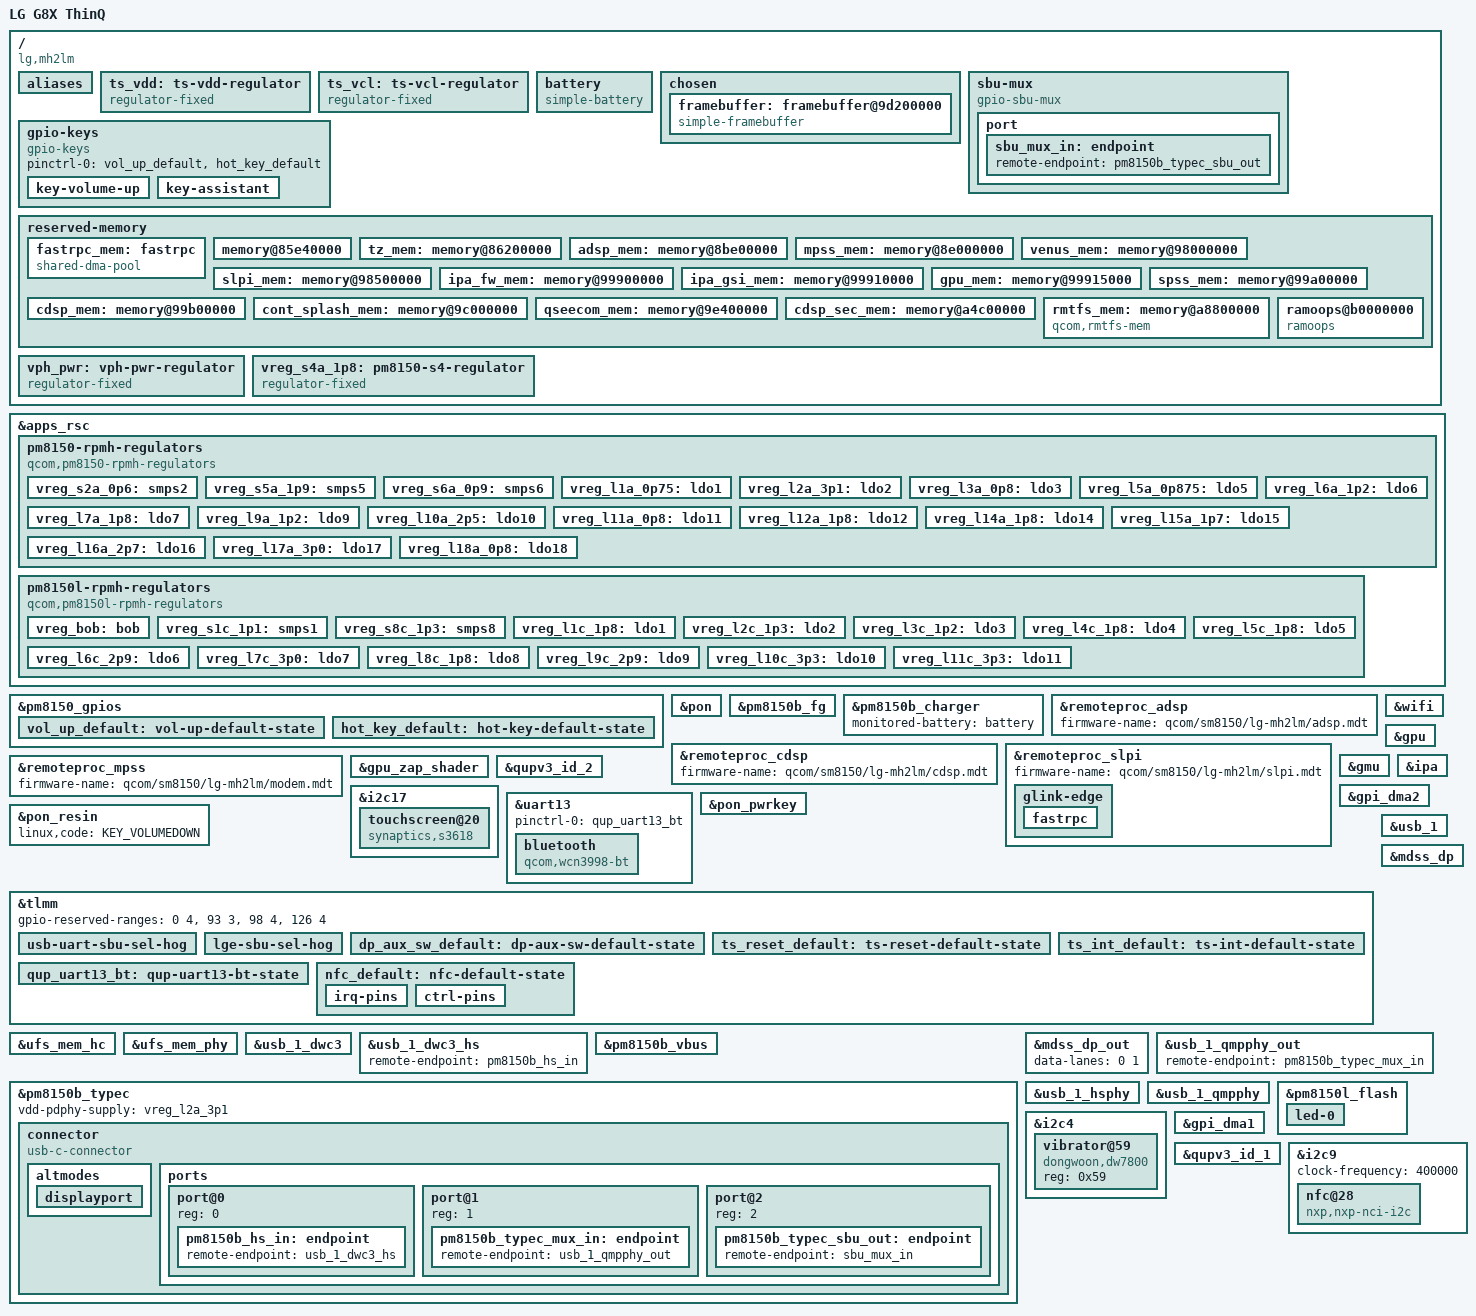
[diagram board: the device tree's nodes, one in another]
// SPDX-License-Identifier: BSD-3-Clause
/*
 * LG G8X ThinQ (mh2lm), first-boot device tree.
 *
 * Reserved memory and regulator limits come from LG's downstream kernel
 * (LineageOS android_kernel_lge_sm8150, lineage-22.2). Regulator structure is
 * based on sm8150-xiaomi-cepheus.dts by Alexey Minnekhanov.
 * Scope: simple framebuffer, buttons, USB gadget, UFS, pstore.
 */

/dts-v1/;

#include <dt-bindings/arm/qcom,ids.h>
#include <dt-bindings/firmware/qcom,scm.h>
#include <dt-bindings/gpio/gpio.h>
#include <dt-bindings/input/input.h>
#include <dt-bindings/input/gpio-keys.h>
#include <dt-bindings/leds/common.h>
#include <dt-bindings/pinctrl/qcom,pmic-gpio.h>
#include <dt-bindings/regulator/qcom,rpmh-regulator.h>
#include <dt-bindings/usb/pd.h>
#include "sm8150.dtsi"
#include "pm8150.dtsi"
#include "pm8150b.dtsi"
#include "pm8150l.dtsi"

/delete-node/ &tz_mem;      /* LG reserves more; the upstream size leaves secure memory mapped */
/delete-node/ &rmtfs_mem;   /* falls inside LG tz_mem; revisit for modem */
/delete-node/ &adsp_mem;
/delete-node/ &mpss_mem;
/delete-node/ &venus_mem;
/delete-node/ &slpi_mem;
/delete-node/ &ipa_fw_mem;
/delete-node/ &ipa_gsi_mem;
/delete-node/ &gpu_mem;
/delete-node/ &spss_mem;
/delete-node/ &cdsp_mem;
/delete-node/ &qseecom_mem;

/ {
	model = "LG G8X ThinQ";
	compatible = "lg,mh2lm", "qcom,sm8150";
	chassis-type = "handset";

	/* Generic board-id, as in the Renegade image LG ABL accepts */
	qcom,msm-id = <QCOM_ID_SM8150 0x20000>;
	qcom,board-id = <0 0>;

	aliases {
		hsuart0 = &uart13;
		display0 = &framebuffer;
	};

	ts_vdd: ts-vdd-regulator {
		compatible = "regulator-fixed";
		regulator-name = "ts_vdd";
		gpio = <&tlmm 152 GPIO_ACTIVE_HIGH>;
		enable-active-high;
		regulator-boot-on;
		regulator-always-on;
	};

	ts_vcl: ts-vcl-regulator {
		compatible = "regulator-fixed";
		regulator-name = "ts_vcl";
		gpio = <&tlmm 59 GPIO_ACTIVE_HIGH>;
		enable-active-high;
		regulator-boot-on;
		regulator-always-on;
	};

	battery: battery {
		compatible = "simple-battery";
		charge-full-design-microamp-hours = <4000000>;
		voltage-min-design-microvolt = <3400000>;
		voltage-max-design-microvolt = <4400000>;
	};

	chosen {
		#address-cells = <2>;
		#size-cells = <2>;
		ranges;

		framebuffer: framebuffer@9d200000 {
			compatible = "simple-framebuffer";
			reg = <0 0x9d200000 0 0x1200000>;
			width = <1080>;
			height = <2340>;
			stride = <(1080 * 4)>;
			format = "a8r8g8b8";
			clocks = <&gcc GCC_DISP_HF_AXI_CLK>,
				 <&gcc GCC_DISP_SF_AXI_CLK>;
		};
	};

	/*
	 * USB-C SBU <-> DP AUX switch. LG drives it with two GPIOs (stock DT
	 * sde_dp qcom,aux-en-gpio 42, enable when low; qcom,aux-sel-gpio 148,
	 * set for the flipped orientation), which is what gpio-sbu-mux does.
	 */
	sbu-mux {
		compatible = "gpio-sbu-mux";
		enable-gpios = <&tlmm 42 GPIO_ACTIVE_LOW>;
		select-gpios = <&tlmm 148 GPIO_ACTIVE_HIGH>;
		pinctrl-0 = <&dp_aux_sw_default>;
		pinctrl-names = "default";
		mode-switch;
		orientation-switch;

		port {
			sbu_mux_in: endpoint {
				remote-endpoint = <&pm8150b_typec_sbu_out>;
			};
		};
	};

	gpio-keys {
		compatible = "gpio-keys";
		pinctrl-names = "default";
		pinctrl-0 = <&vol_up_default &hot_key_default>;

		key-volume-up {
			label = "Volume Up";
			gpios = <&pm8150_gpios 6 GPIO_ACTIVE_LOW>;
			linux,code = <KEY_VOLUMEUP>;
			debounce-interval = <15>;
			wakeup-source;
		};

		key-assistant {
			label = "Google Assistant";
			gpios = <&pm8150_gpios 1 GPIO_ACTIVE_LOW>;
			linux,code = <KEY_ASSISTANT>;
			debounce-interval = <15>;
		};
	};

	reserved-memory {
		fastrpc_mem: fastrpc {
			compatible = "shared-dma-pool";
			alloc-ranges = <0x0 0x00000000 0x0 0xffffffff>;
			alignment = <0x0 0x400000>;
			size = <0x0 0x1000000>;
			reusable;
		};

		/* Tail of LG xbl_aop_mem not covered by the upstream xbl/aop regions */
		memory@85e40000 {
			reg = <0x0 0x85e40000 0x0 0xc0000>;
			no-map;
		};

		tz_mem: memory@86200000 {
			reg = <0x0 0x86200000 0x0 0x5500000>;
			no-map;
		};

		adsp_mem: memory@8be00000 {
			reg = <0x0 0x8be00000 0x0 0x2200000>;
			no-map;
		};

		mpss_mem: memory@8e000000 {
			reg = <0x0 0x8e000000 0x0 0xa000000>;
			no-map;
		};

		venus_mem: memory@98000000 {
			reg = <0x0 0x98000000 0x0 0x500000>;
			no-map;
		};

		slpi_mem: memory@98500000 {
			reg = <0x0 0x98500000 0x0 0x1400000>;
			no-map;
		};

		ipa_fw_mem: memory@99900000 {
			reg = <0x0 0x99900000 0x0 0x10000>;
			no-map;
		};

		ipa_gsi_mem: memory@99910000 {
			reg = <0x0 0x99910000 0x0 0x5000>;
			no-map;
		};

		gpu_mem: memory@99915000 {
			reg = <0x0 0x99915000 0x0 0x2000>;
			no-map;
		};

		spss_mem: memory@99a00000 {
			reg = <0x0 0x99a00000 0x0 0x100000>;
			no-map;
		};

		cdsp_mem: memory@99b00000 {
			reg = <0x0 0x99b00000 0x0 0x1400000>;
			no-map;
		};

		cont_splash_mem: memory@9c000000 {
			reg = <0x0 0x9c000000 0x0 0x2400000>;
			no-map;
		};

		qseecom_mem: memory@9e400000 {
			reg = <0x0 0x9e400000 0x0 0x1c00000>;
			no-map;
		};

		cdsp_sec_mem: memory@a4c00000 {
			reg = <0x0 0xa4c00000 0x0 0x3c00000>;
			no-map;
		};

		rmtfs_mem: memory@a8800000 {
			compatible = "qcom,rmtfs-mem";
			reg = <0x0 0xa8800000 0x0 0x200000>;
			no-map;

			qcom,client-id = <1>;
			qcom,vmid = <15>;
		};

		ramoops@b0000000 {
			compatible = "ramoops";
			reg = <0x0 0xb0000000 0x0 0x300000>;
			record-size = <0x1000>;
			console-size = <0x40000>;
			ftrace-size = <0x40000>;
			pmsg-size = <0x200000>;
			ecc-size = <0>;
		};
	};

	vph_pwr: vph-pwr-regulator {
		compatible = "regulator-fixed";
		regulator-name = "vph_pwr";
		regulator-min-microvolt = <3700000>;
		regulator-max-microvolt = <3700000>;
	};

	/* S4 is modeled as a fixed regulator in vendor sources */
	vreg_s4a_1p8: pm8150-s4-regulator {
		compatible = "regulator-fixed";
		regulator-name = "vreg_s4a_1p8";
		regulator-min-microvolt = <1800000>;
		regulator-max-microvolt = <1800000>;
		regulator-always-on;
		regulator-boot-on;
		vin-supply = <&vph_pwr>;
	};
};

&apps_rsc {
	pm8150-rpmh-regulators {
		compatible = "qcom,pm8150-rpmh-regulators";
		qcom,pmic-id = "a";

		vdd-s1-supply = <&vph_pwr>;
		vdd-s2-supply = <&vph_pwr>;
		vdd-s3-supply = <&vph_pwr>;
		vdd-s4-supply = <&vph_pwr>;
		vdd-s5-supply = <&vph_pwr>;
		vdd-s6-supply = <&vph_pwr>;
		vdd-s7-supply = <&vph_pwr>;
		vdd-s8-supply = <&vph_pwr>;
		vdd-s9-supply = <&vph_pwr>;
		vdd-s10-supply = <&vph_pwr>;

		vdd-l1-l8-l11-supply = <&vreg_s6a_0p9>;
		vdd-l2-l10-supply = <&vreg_bob>;
		vdd-l3-l4-l5-l18-supply = <&vreg_s6a_0p9>;
		vdd-l6-l9-supply = <&vreg_s8c_1p3>;
		vdd-l7-l12-l14-l15-supply = <&vreg_s5a_1p9>;
		vdd-l13-l16-l17-supply = <&vreg_bob>;

		vreg_s2a_0p6: smps2 {
			regulator-min-microvolt = <600000>;
			regulator-max-microvolt = <600000>;
			regulator-initial-mode = <RPMH_REGULATOR_MODE_HPM>;
			regulator-name = "pm8150_s2a_0p6";
		};

		vreg_s5a_1p9: smps5 {
			regulator-min-microvolt = <1904000>;
			regulator-max-microvolt = <2040000>;
			regulator-initial-mode = <RPMH_REGULATOR_MODE_HPM>;
			regulator-name = "pm8150_s5a_0p6";
		};

		vreg_s6a_0p9: smps6 {
			regulator-min-microvolt = <920000>;
			regulator-max-microvolt = <1128000>;
			regulator-initial-mode = <RPMH_REGULATOR_MODE_HPM>;
			regulator-name = "pm8150_s6a_0p9";
		};

		vreg_l1a_0p75: ldo1 {
			regulator-min-microvolt = <752000>;
			regulator-max-microvolt = <752000>;
			regulator-initial-mode = <RPMH_REGULATOR_MODE_HPM>;
			regulator-name = "pm8150_l1a_0p75";
		};

		vreg_l2a_3p1: ldo2 {
			regulator-min-microvolt = <3072000>;
			regulator-max-microvolt = <3072000>;
			regulator-initial-mode = <RPMH_REGULATOR_MODE_HPM>;
			regulator-name = "pm8150_l2a_3p1";
		};

		vreg_l3a_0p8: ldo3 {
			regulator-min-microvolt = <480000>;
			regulator-max-microvolt = <932000>;
			regulator-initial-mode = <RPMH_REGULATOR_MODE_HPM>;
			regulator-name = "pm8150_l3a_0p8";
		};

		vreg_l5a_0p875: ldo5 {
			regulator-min-microvolt = <880000>;
			regulator-max-microvolt = <880000>;
			regulator-initial-mode = <RPMH_REGULATOR_MODE_HPM>;
			regulator-name = "pm8150_l5a_0p875";
		};

		vreg_l6a_1p2: ldo6 {
			regulator-min-microvolt = <1200000>;
			regulator-max-microvolt = <1200000>;
			regulator-initial-mode = <RPMH_REGULATOR_MODE_HPM>;
			regulator-name = "pm8150_l6a_1p2";
		};

		vreg_l7a_1p8: ldo7 {
			regulator-min-microvolt = <1800000>;
			regulator-max-microvolt = <1800000>;
			regulator-initial-mode = <RPMH_REGULATOR_MODE_HPM>;
			regulator-name = "pm8150_l7a_1p8";
		};

		vreg_l9a_1p2: ldo9 {
			regulator-min-microvolt = <1200000>;
			regulator-max-microvolt = <1200000>;
			regulator-initial-mode = <RPMH_REGULATOR_MODE_HPM>;
			regulator-name = "pm8150_l9a_1p2";
		};

		vreg_l10a_2p5: ldo10 {
			regulator-min-microvolt = <2950000>;
			regulator-max-microvolt = <2960000>;
			regulator-initial-mode = <RPMH_REGULATOR_MODE_HPM>;
			regulator-name = "pm8150_l10a_2p5";
		};

		vreg_l11a_0p8: ldo11 {
			regulator-min-microvolt = <800000>;
			regulator-max-microvolt = <800000>;
			regulator-initial-mode = <RPMH_REGULATOR_MODE_HPM>;
			regulator-name = "pm8150_l11a_0p8";
		};

		vreg_l12a_1p8: ldo12 {
			regulator-min-microvolt = <1800000>;
			regulator-max-microvolt = <1800000>;
			regulator-initial-mode = <RPMH_REGULATOR_MODE_HPM>;
			regulator-name = "pm8150_l12a_1p8";
		};

		/* L13 is unused, but min/max are 3000000 for it. */

		vreg_l14a_1p8: ldo14 {
			regulator-min-microvolt = <1800000>;
			regulator-max-microvolt = <1880000>;
			regulator-initial-mode = <RPMH_REGULATOR_MODE_HPM>;
			regulator-name = "pm8150_l14a_1p8";
			regulator-always-on;
		};

		vreg_l15a_1p7: ldo15 {
			regulator-min-microvolt = <1704000>;
			regulator-max-microvolt = <1704000>;
			regulator-initial-mode = <RPMH_REGULATOR_MODE_HPM>;
			regulator-name = "pm8150_l15a_1p7";
		};

		vreg_l16a_2p7: ldo16 {
			regulator-min-microvolt = <2704000>;
			regulator-max-microvolt = <2960000>;
			regulator-initial-mode = <RPMH_REGULATOR_MODE_HPM>;
			regulator-name = "pm8150_l16a_2p7";
		};

		vreg_l17a_3p0: ldo17 {
			regulator-min-microvolt = <2856000>;
			regulator-max-microvolt = <3008000>;
			regulator-initial-mode = <RPMH_REGULATOR_MODE_HPM>;
			regulator-name = "pm8150_l17a_3p0";
			regulator-always-on;
		};

		vreg_l18a_0p8: ldo18 {
			regulator-min-microvolt = <880000>;
			regulator-max-microvolt = <912000>;
			regulator-initial-mode = <RPMH_REGULATOR_MODE_HPM>;
			regulator-name = "pm8150_l18a_0p8";
		};
	};

	pm8150l-rpmh-regulators {
		compatible = "qcom,pm8150l-rpmh-regulators";
		qcom,pmic-id = "c";

		vdd-s1-supply = <&vph_pwr>;
		vdd-s2-supply = <&vph_pwr>;
		vdd-s3-supply = <&vph_pwr>;
		vdd-s4-supply = <&vph_pwr>;
		vdd-s5-supply = <&vph_pwr>;
		vdd-s6-supply = <&vph_pwr>;
		vdd-s7-supply = <&vph_pwr>;
		vdd-s8-supply = <&vph_pwr>;

		vdd-l1-l8-supply = <&vreg_s4a_1p8>;
		vdd-l2-l3-supply = <&vreg_s8c_1p3>;
		vdd-l4-l5-l6-supply = <&vreg_bob>;
		vdd-l7-l11-supply = <&vreg_bob>;
		vdd-l9-l10-supply = <&vreg_bob>;

		vdd-bob-supply = <&vph_pwr>;
		vdd-flash-supply = <&vreg_bob>;
		vdd-rgb-supply = <&vreg_bob>;

		vreg_bob: bob {
			regulator-min-microvolt = <3008000>;
			regulator-max-microvolt = <4000000>;
			regulator-initial-mode = <RPMH_REGULATOR_MODE_AUTO>;
			regulator-allow-bypass;
			regulator-name = "pm8150l_bob";
		};

		vreg_s1c_1p1: smps1 {
			regulator-min-microvolt = <1128000>;
			regulator-max-microvolt = <1128000>;
			regulator-initial-mode = <RPMH_REGULATOR_MODE_HPM>;
			regulator-name = "pm8150l_s1c_1p1";
		};

		vreg_s8c_1p3: smps8 {
			regulator-min-microvolt = <1352000>;
			regulator-max-microvolt = <1352000>;
			regulator-initial-mode = <RPMH_REGULATOR_MODE_HPM>;
			regulator-name = "pm8150l_s8c_1p3";
		};

		vreg_l1c_1p8: ldo1 {
			regulator-min-microvolt = <1800000>;
			regulator-max-microvolt = <1800000>;
			regulator-initial-mode = <RPMH_REGULATOR_MODE_HPM>;
			regulator-name = "pm8150l_l1c_1p8";
		};

		vreg_l2c_1p3: ldo2 {
			regulator-min-microvolt = <1304000>;
			regulator-max-microvolt = <1304000>;
			regulator-initial-mode = <RPMH_REGULATOR_MODE_HPM>;
			regulator-name = "pm8150l_l2c_1p3";
		};

		vreg_l3c_1p2: ldo3 {
			regulator-min-microvolt = <1200000>;
			regulator-max-microvolt = <1200000>;
			regulator-initial-mode = <RPMH_REGULATOR_MODE_HPM>;
			regulator-name = "pm8150l_l3c_1p2";
		};

		vreg_l4c_1p8: ldo4 {
			regulator-min-microvolt = <1704000>;
			regulator-max-microvolt = <2928000>;
			regulator-initial-mode = <RPMH_REGULATOR_MODE_HPM>;
			regulator-name = "pm8150l_l4c_1p8";
		};

		vreg_l5c_1p8: ldo5 {
			regulator-min-microvolt = <1704000>;
			regulator-max-microvolt = <2928000>;
			regulator-initial-mode = <RPMH_REGULATOR_MODE_HPM>;
			regulator-name = "pm8150l_l5c_1p8";
		};

		vreg_l6c_2p9: ldo6 {
			regulator-min-microvolt = <1800000>;
			regulator-max-microvolt = <2960000>;
			regulator-initial-mode = <RPMH_REGULATOR_MODE_HPM>;
			regulator-allow-set-load;
			regulator-name = "pm8150l_l6c_2p9";
		};

		vreg_l7c_3p0: ldo7 {
			regulator-min-microvolt = <2856000>;
			regulator-max-microvolt = <3104000>;
			regulator-initial-mode = <RPMH_REGULATOR_MODE_HPM>;
			regulator-name = "pm8150l_l7c_3p0";
		};

		vreg_l8c_1p8: ldo8 {
			regulator-min-microvolt = <1800000>;
			regulator-max-microvolt = <1800000>;
			regulator-initial-mode = <RPMH_REGULATOR_MODE_HPM>;
			regulator-name = "pm8150l_l8c_1p8";
		};

		vreg_l9c_2p9: ldo9 {
			regulator-min-microvolt = <2704000>;
			regulator-max-microvolt = <2960000>;
			regulator-initial-mode = <RPMH_REGULATOR_MODE_HPM>;
			regulator-allow-set-load;
			regulator-name = "pm8150l_l9c_2p9";
		};

		vreg_l10c_3p3: ldo10 {
			regulator-min-microvolt = <3104000>;
			regulator-max-microvolt = <3312000>;
			regulator-initial-mode = <RPMH_REGULATOR_MODE_HPM>;
			regulator-name = "pm8150l_l10c_3p3";
		};

		vreg_l11c_3p3: ldo11 {
			regulator-min-microvolt = <3104000>;
			regulator-max-microvolt = <3312000>;
			regulator-initial-mode = <RPMH_REGULATOR_MODE_HPM>;
			regulator-name = "pm8150l_l11c_3p3";
		};
	};
};

&pm8150_gpios {
	vol_up_default: vol-up-default-state {
		pins = "gpio6";
		function = "normal";
		input-enable;
		bias-pull-up;
		qcom,drive-strength = <PMIC_GPIO_STRENGTH_NO>;
	};

	hot_key_default: hot-key-default-state {
		pins = "gpio1";
		function = "normal";
		input-enable;
		bias-pull-up;
		qcom,drive-strength = <PMIC_GPIO_STRENGTH_NO>;
	};
};

&pon {
	mode-bootloader = <0x2>;
	mode-recovery = <0x1>;
};

&pm8150b_fg {
	status = "okay";
	monitored-battery = <&battery>;
	power-supplies = <&pm8150b_charger>;
};

&pm8150b_charger {
	status = "okay";
	monitored-battery = <&battery>;
};

&remoteproc_adsp {
	status = "okay";
	firmware-name = "qcom/sm8150/lg-mh2lm/adsp.mdt";
};

&remoteproc_cdsp {
	status = "okay";
	firmware-name = "qcom/sm8150/lg-mh2lm/cdsp.mdt";
};

&remoteproc_slpi {
	status = "okay";
	firmware-name = "qcom/sm8150/lg-mh2lm/slpi.mdt";

	glink-edge {
		fastrpc {
			memory-region = <&fastrpc_mem>;
			qcom,vmids = <QCOM_SCM_VMID_HLOS QCOM_SCM_VMID_SSC_Q6
				      QCOM_SCM_VMID_ADSP_Q6>;
		};
	};
};

&remoteproc_mpss {
	status = "okay";
	firmware-name = "qcom/sm8150/lg-mh2lm/modem.mdt";
};

&wifi {
	status = "okay";

	vdd-0.8-cx-mx-supply = <&vreg_l1a_0p75>;
	vdd-1.8-xo-supply = <&vreg_l7a_1p8>;
	vdd-1.3-rfa-supply = <&vreg_l2c_1p3>;
	vdd-3.3-ch0-supply = <&vreg_l11c_3p3>;
	vdd-3.3-ch1-supply = <&vreg_l10c_3p3>;
};

&gpu {
	status = "okay";
};

&gmu {
	status = "okay";
};

&gpu_zap_shader {
	firmware-name = "qcom/sm8150/lg-mh2lm/a640_zap.mdt";
};

&qupv3_id_2 {
	status = "okay";
};

&ipa {
	status = "okay";
	qcom,gsi-loader = "self";
	memory-region = <&ipa_fw_mem>;
	firmware-name = "qcom/sm8150/lg-mh2lm/ipa_fws.mdt";
};

&i2c17 {
	status = "okay";

	touchscreen@20 {
		compatible = "synaptics,s3618";
		reg = <0x20>;
		interrupts-extended = <&tlmm 122 IRQ_TYPE_LEVEL_LOW>;
		reset-gpios = <&tlmm 54 GPIO_ACTIVE_LOW>;
		pinctrl-names = "default";
		pinctrl-0 = <&ts_reset_default>, <&ts_int_default>;
		touchscreen-size-x = <1080>;
		touchscreen-size-y = <2340>;
	};
};

&gpi_dma2 {
	status = "okay";
};

&uart13 {
	status = "okay";

	pinctrl-names = "default";
	pinctrl-0 = <&qup_uart13_bt>;

	bluetooth: bluetooth {
		local-bd-address = [67 FE 43 67 2A 02];
		compatible = "qcom,wcn3998-bt";
		vddio-supply = <&vreg_l7a_1p8>;
		vddxo-supply = <&vreg_l7a_1p8>;
		vddrf-supply = <&vreg_l2c_1p3>;
		vddch0-supply = <&vreg_l11c_3p3>;
		vddch1-supply = <&vreg_l10c_3p3>;
		max-speed = <3200000>;
		firmware-name = "crnv21.bin", "crbtfw21.tlv";
	};
};

&pon_pwrkey {
	status = "okay";
};

&pon_resin {
	linux,code = <KEY_VOLUMEDOWN>;
	status = "okay";
};

&tlmm {
	/* secure-world SPI ranges, same conservative set as the SM8150 reference boards */
	gpio-reserved-ranges = <0 4>, <93 3>, <98 4>, <126 4>; /* LG lge,access-denied-gpios confirmed by boot testing */

	/*
	 * USB-C SBU routing (stock lge_usb_debugger / lge_sbu_switch). The
	 * bootloader leaves GPIO 35 high, which routes SBU to LG's debug UART:
	 * DP AUX then times out (-110). Low = SBU to the DP AUX switch.
	 * GPIO 87 (LG SBU switch select) stays high as on stock.
	 */
	usb-uart-sbu-sel-hog {
		gpio-hog;
		gpios = <35 GPIO_ACTIVE_HIGH>;
		output-low;
		line-name = "usb-uart-sbu-sel";
	};

	lge-sbu-sel-hog {
		gpio-hog;
		gpios = <87 GPIO_ACTIVE_HIGH>;
		output-high;
		line-name = "lge-sbu-sel";
	};

	dp_aux_sw_default: dp-aux-sw-default-state {
		pins = "gpio42", "gpio148";
		function = "gpio";
		drive-strength = <2>;
		bias-disable;
	};

	ts_reset_default: ts-reset-default-state {
		pins = "gpio54";
		function = "gpio";
		drive-strength = <6>;
		bias-pull-up;
	};

	ts_int_default: ts-int-default-state {
		pins = "gpio122";
		function = "gpio";
		drive-strength = <2>;
		bias-pull-up;
	};

	qup_uart13_bt: qup-uart13-bt-state {
		pins = "gpio43", "gpio44", "gpio45", "gpio46";
		function = "qup13";
		drive-strength = <2>;
		bias-disable;
	};
};

&ufs_mem_hc {
	status = "okay";

	reset-gpios = <&tlmm 175 GPIO_ACTIVE_LOW>;

	vcc-supply = <&vreg_l10a_2p5>;
	vcc-max-microamp = <750000>;
	vccq-supply = <&vreg_l9a_1p2>;
	vccq-max-microamp = <700000>;
	vccq2-supply = <&vreg_s4a_1p8>;
	vccq2-max-microamp = <750000>;
};

&ufs_mem_phy {
	status = "okay";

	vdda-phy-supply = <&vreg_l5a_0p875>;
	vdda-pll-supply = <&vreg_l3c_1p2>;
};

&usb_1 {
	status = "okay";
};

&usb_1_dwc3 {
	dr_mode = "otg";
	usb-role-switch;
	maximum-speed = "high-speed";
};

&usb_1_dwc3_hs {
	remote-endpoint = <&pm8150b_hs_in>;
};

/* USB-C: PM8150B Type-C/PD port with DisplayPort alt mode (stock: sde_dp
 * with qcom,dp-usbpd-detection = <&pm8150b_pdphy>). */
&pm8150b_vbus {
	regulator-min-microamp = <500000>;
	regulator-max-microamp = <1500000>;
	status = "okay";
};

&pm8150b_typec {
	vdd-pdphy-supply = <&vreg_l2a_3p1>;
	status = "okay";

	connector {
		compatible = "usb-c-connector";

		power-role = "dual";
		try-power-role = "sink";
		data-role = "dual";

		source-pdos = <PDO_FIXED(5000, 1500,
					 PDO_FIXED_DUAL_ROLE |
					 PDO_FIXED_USB_COMM |
					 PDO_FIXED_DATA_SWAP)>;
		sink-pdos = <PDO_FIXED(5000, 3000,
				       PDO_FIXED_DUAL_ROLE |
				       PDO_FIXED_USB_COMM |
				       PDO_FIXED_DATA_SWAP)>;
		op-sink-microwatt = <10000000>;

		altmodes {
			displayport {
				svid = /bits/ 16 <0xff01>;
				vdo = <0x00001c46>;
			};
		};

		ports {
			#address-cells = <1>;
			#size-cells = <0>;

			port@0 {
				reg = <0>;
				pm8150b_hs_in: endpoint {
					remote-endpoint = <&usb_1_dwc3_hs>;
				};
			};

			port@1 {
				reg = <1>;
				pm8150b_typec_mux_in: endpoint {
					remote-endpoint = <&usb_1_qmpphy_out>;
				};
			};

			port@2 {
				reg = <2>;
				pm8150b_typec_sbu_out: endpoint {
					remote-endpoint = <&sbu_mux_in>;
				};
			};
		};
	};
};

&mdss_dp {
	status = "okay";
};

&mdss_dp_out {
	data-lanes = <0 1>;
};

&usb_1_qmpphy_out {
	remote-endpoint = <&pm8150b_typec_mux_in>;
};

&usb_1_hsphy {
	status = "okay";

	vdda-pll-supply = <&vreg_l5a_0p875>;
	vdda18-supply = <&vreg_l12a_1p8>;
	vdda33-supply = <&vreg_l2a_3p1>;
};

&usb_1_qmpphy {
	status = "okay";

	vdda-phy-supply = <&vreg_l3c_1p2>;
	/* stock ssphy@88e8000 vdd-supply = pm8150_l18 (912 mV); with l5a the
	 * PHY init times out the first time USB3/DP lanes are used */
	vdda-pll-supply = <&vreg_l18a_0p8>;
	mode-switch;
	orientation-switch;
};

/* Rear flash/torch: two LEDs on PM8150L flash channels 1+2, ganged.
 * LG: torch 100 mA and flash 800 mA per channel, 500 ms flash. */
&pm8150l_flash {
	status = "okay";

	led-0 {
		function = LED_FUNCTION_FLASH;
		color = <LED_COLOR_ID_WHITE>;
		led-sources = <1>, <2>;
		led-max-microamp = <200000>;	/* split across both channels */
		flash-max-microamp = <1600000>;
		flash-max-timeout-us = <500000>;
	};
};

/* Vibration: Dongwoon DW7800 LRA driver on QUP SE4 I2C (LG dw7800@59). */
&i2c4 {
	vibrator@59 {
		compatible = "dongwoon,dw7800";
		reg = <0x59>;
	};
};

/* NFC: NXP PN553-family NCI controller on QUP SE9 I2C (LG nq@28):
 * IRQ gpio47, VEN (enable) gpio41, firmware-download gpio48. */
&gpi_dma1 {
	status = "okay";
};

&qupv3_id_1 {
	status = "okay";
};

&i2c9 {
	status = "okay";
	clock-frequency = <400000>;

	nfc@28 {
		compatible = "nxp,nxp-nci-i2c";
		reg = <0x28>;
		interrupts-extended = <&tlmm 47 IRQ_TYPE_EDGE_RISING>;
		enable-gpios = <&tlmm 41 GPIO_ACTIVE_HIGH>;
		firmware-gpios = <&tlmm 48 GPIO_ACTIVE_HIGH>;
		pinctrl-0 = <&nfc_default>;
		pinctrl-names = "default";
	};
};

&tlmm {
	nfc_default: nfc-default-state {
		irq-pins {
			pins = "gpio47";
			function = "gpio";
			drive-strength = <2>;
			bias-pull-down;
		};
		ctrl-pins {
			pins = "gpio41", "gpio48";
			function = "gpio";
			drive-strength = <2>;
			bias-disable;
		};
	};
};
